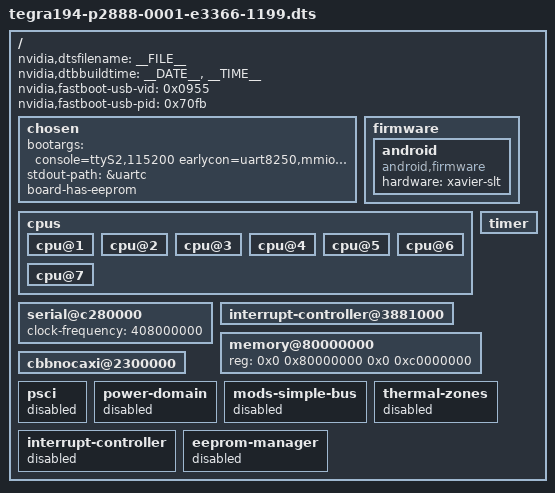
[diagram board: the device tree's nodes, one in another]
/*
 * Top level DTS file for CVM:P2888-0001 and CVB:E3366-1199
 *
 * Copyright (c) 2017-2018, NVIDIA CORPORATION.  All rights reserved.
 *
 * This program is free software; you can redistribute it and/or modify
 * it under the terms of the GNU General Public License as published by
 * the Free Software Foundation; version 2 of the License.
 *
 * This program is distributed in the hope that it will be useful, but WITHOUT
 * ANY WARRANTY; without even the implied warranty of MERCHANTABILITY or
 * FITNESS FOR A PARTICULAR PURPOSE.  See the GNU General Public License for
 * more details.
 */

#include "common/tegra194-p2888-0000-a00.dtsi"
#include "common/tegra194-e3366-1199-a00.dtsi"
#include "common/tegra194-power-tree-p2888-0001-e3366-1199.dtsi"
/ {
	nvidia,dtsfilename = __FILE__;
	nvidia,dtbbuildtime = __DATE__, __TIME__;
	nvidia,fastboot-usb-vid = <0x0955>;
	nvidia,fastboot-usb-pid = <0x70fb>;

	chosen {
		bootargs ="console=ttyS2,115200 earlycon=uart8250,mmio32,0x0c280000";
		stdout-path = &uartc;
		board-has-eeprom;
	};

	firmware {
		android {
			compatible = "android,firmware";
			hardware = "xavier-slt";
		};
	};

	cpus {
		cpu@1 {
			status = "okay";
		};

		cpu@2 {
			status = "okay";
		};

		cpu@3 {
			status = "okay";
		};

		cpu@4 {
			status = "okay";
		};

		cpu@5 {
			status = "okay";
		};

		cpu@6 {
			status = "okay";
		};

		cpu@7 {
			status = "okay";
		};

	};

	timer {
		status = "okay";
	};

	serial@c280000 {
		clock-frequency = <408000000>;
		status = "okay";
	};

	interrupt-controller@3881000 {
		status = "okay";
	};

	memory@80000000 {
		device_type = "memory";
		reg = <0x0 0x80000000 0x0 0xc0000000>;
	};

	cbbnocaxi@2300000 {
		status = "okay";
	};

	psci {
		status = "disabled";
	};

	power-domain {
		status = "disabled";
	};

	mods-simple-bus {
		status = "disabled";
	};

	thermal-zones {
		status = "disabled";
	};

	interrupt-controller {
		status = "disabled";
	};

	eeprom-manager {
		status = "disabled";
	};
};
